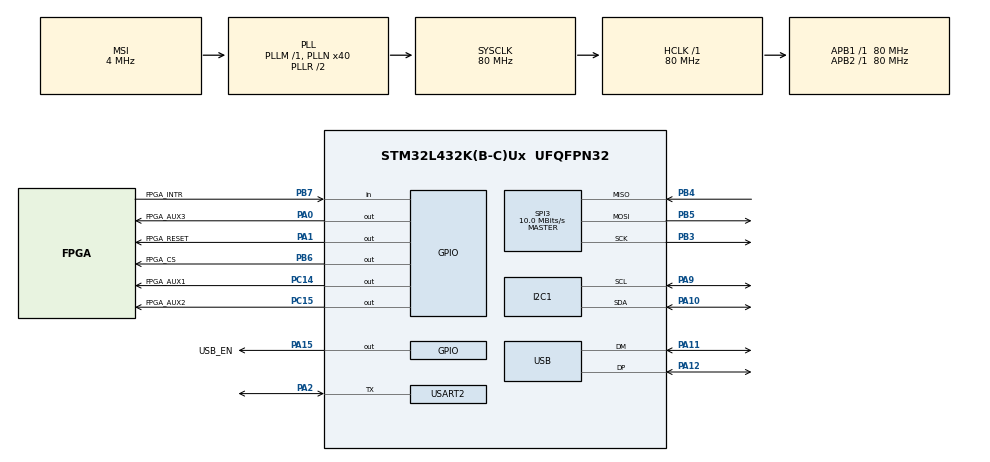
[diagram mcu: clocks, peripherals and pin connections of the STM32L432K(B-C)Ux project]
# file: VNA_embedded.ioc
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Dma.Request0=SPI3_RX
Dma.Request1=SPI3_TX
Dma.SPI3_RX.0.Direction=DMA_PERIPH_TO_MEMORY
Dma.SPI3_RX.0.Instance=DMA2_Channel1
Dma.SPI3_RX.0.MemDataAlignment=DMA_MDATAALIGN_HALFWORD
Dma.SPI3_RX.0.MemInc=DMA_MINC_ENABLE
Dma.SPI3_RX.0.Mode=DMA_NORMAL
Dma.SPI3_RX.0.PeriphDataAlignment=DMA_PDATAALIGN_HALFWORD
Dma.SPI3_RX.0.PeriphInc=DMA_PINC_DISABLE
Dma.SPI3_RX.0.Priority=DMA_PRIORITY_HIGH
Dma.SPI3_TX.1.Direction=DMA_MEMORY_TO_PERIPH
Dma.SPI3_TX.1.Instance=DMA2_Channel2
Dma.SPI3_TX.1.MemDataAlignment=DMA_MDATAALIGN_HALFWORD
Dma.SPI3_TX.1.MemInc=DMA_MINC_ENABLE
Dma.SPI3_TX.1.Mode=DMA_NORMAL
Dma.SPI3_TX.1.PeriphDataAlignment=DMA_PDATAALIGN_HALFWORD
Dma.SPI3_TX.1.PeriphInc=DMA_PINC_DISABLE
Dma.SPI3_TX.1.Priority=DMA_PRIORITY_HIGH
FREERTOS.MEMORY_ALLOCATION=1
FREERTOS.Tasks01=defaultTask,0,1024,StartDefaultTask,Default,NULL,Static,defaultTaskBuffer,defaultTaskControlBlock
Mcu.Family=STM32L4
Mcu.Name=STM32L432K(B-C)Ux
Mcu.Package=UFQFPN32
NVIC.DMA2_Channel1_IRQn=true\:5\:0\:true\:false\:true\:true\:false\:true
NVIC.DMA2_Channel2_IRQn=true\:5\:0\:true\:false\:true\:true\:false\:true
NVIC.PriorityGroup=NVIC_PRIORITYGROUP_4
NVIC.TIM1_UP_TIM16_IRQn=true\:0\:0\:false\:false\:true\:false\:false\:true
NVIC.TimeBase=TIM1_UP_TIM16_IRQn
NVIC.TimeBaseIP=TIM16
NVIC.USB_IRQn=true\:5\:0\:true\:false\:true\:true\:true\:true
PA0.GPIO_Label=FPGA_AUX3
PA0.GPIO_Speed=GPIO_SPEED_FREQ_VERY_HIGH
PA0.Signal=GPIO_Output
PA1.GPIO_Label=FPGA_RESET
PA1.GPIO_Speed=GPIO_SPEED_FREQ_VERY_HIGH
PA1.Signal=GPIO_Output
PA10.Mode=I2C
PA10.Signal=I2C1_SDA
PA11.Mode=Device
PA11.Signal=USB_DM
PA12.Mode=Device
PA12.Signal=USB_DP
PA13\ (JTMS-SWDIO).Mode=Serial_Wire
PA13\ (JTMS-SWDIO).Signal=SYS_JTMS-SWDIO
PA14\ (JTCK-SWCLK).Mode=Serial_Wire
PA14\ (JTCK-SWCLK).Signal=SYS_JTCK-SWCLK
PA15\ (JTDI).GPIO_Label=USB_EN
PA15\ (JTDI).Signal=GPIO_Output
PA2.Mode=Half_duplex(single_wire_mode)
PA2.Signal=USART2_TX
PA9.Mode=I2C
PA9.Signal=I2C1_SCL
PB3\ (JTDO-TRACESWO).Mode=Full_Duplex_Master
PB3\ (JTDO-TRACESWO).Signal=SPI3_SCK
PB4\ (NJTRST).Mode=Full_Duplex_Master
PB4\ (NJTRST).Signal=SPI3_MISO
PB5.Mode=Full_Duplex_Master
PB5.Signal=SPI3_MOSI
PB6.GPIO_Label=FPGA_CS
PB6.GPIO_Speed=GPIO_SPEED_FREQ_VERY_HIGH
PB6.Signal=GPIO_Output
PB7.GPIO_Label=FPGA_INTR
PB7.Signal=GPIO_Input
PC14-OSC32_IN\ (PC14).GPIO_Label=FPGA_AUX1
PC14-OSC32_IN\ (PC14).Signal=GPIO_Output
PC15-OSC32_OUT\ (PC15).GPIO_Label=FPGA_AUX2
PC15-OSC32_OUT\ (PC15).Signal=GPIO_Output
ProjectManager.HeapSize=0x200
ProjectManager.StackSize=0x400
ProjectManager.TargetToolchain=SW4STM32
RCC.ADCFreq_Value=48000000
RCC.AHBFreq_Value=80000000
RCC.APB1Freq_Value=80000000
RCC.APB1TimFreq_Value=80000000
RCC.APB2Freq_Value=80000000
RCC.APB2TimFreq_Value=80000000
RCC.CortexFreq_Value=80000000
RCC.HCLKFreq_Value=80000000
RCC.HSE_VALUE=8000000
RCC.HSI48_VALUE=48000000
RCC.HSI_VALUE=16000000
RCC.LSE_VALUE=32768
RCC.MSI_VALUE=4000000
RCC.PLLN=40
RCC.PLLSAI1N=24
RCC.SYSCLKFreq_VALUE=80000000
RCC.SYSCLKSource=RCC_SYSCLKSOURCE_PLLCLK
RCC.USBFreq_Value=48000000
RCC.VCOOutputFreq_Value=160000000
SPI3.BaudRatePrescaler=SPI_BAUDRATEPRESCALER_8
SPI3.CalculateBaudRate=10.0 MBits/s
SPI3.DataSize=SPI_DATASIZE_16BIT
SPI3.Direction=SPI_DIRECTION_2LINES
SPI3.Mode=SPI_MODE_MASTER
SPI3.VirtualType=VM_MASTER
TIM1.Period=65535
TIM1.Prescaler=79
USART2.VirtualMode-Half_duplex(single_wire_mode)=VM_ASYNC
VP_FREERTOS_VS_CMSIS_V1.Mode=CMSIS_V1
VP_SYS_VS_tim16.Mode=TIM16
VP_TIM1_VS_ClockSourceINT.Mode=Internal
board=custom

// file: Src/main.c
/* USER CODE BEGIN Header */
/**
  ******************************************************************************
  * @file           : main.c
  * @brief          : Main program body
  ******************************************************************************
  * @attention
  *
  * <h2><center>&copy; Copyright (c) 2020 STMicroelectronics.
  * All rights reserved.</center></h2>
  *
  * This software component is licensed by ST under Ultimate Liberty license
  * SLA0044, the "License"; You may not use this file except in compliance with
  * the License. You may obtain a copy of the License at:
  *                             www.st.com/SLA0044
  *
  ******************************************************************************
  */
/* USER CODE END Header */

#include "main.h"
#include "cmsis_os.h"

/* USER CODE BEGIN Includes */
#include "App.h"
/* USER CODE END Includes */

I2C_HandleTypeDef hi2c1;

SPI_HandleTypeDef hspi3;
DMA_HandleTypeDef hdma_spi3_rx;
DMA_HandleTypeDef hdma_spi3_tx;

TIM_HandleTypeDef htim1;

UART_HandleTypeDef huart2;

PCD_HandleTypeDef hpcd_USB_FS;

osThreadId defaultTaskHandle;
uint32_t defaultTaskBuffer[ 1024 ];
osStaticThreadDef_t defaultTaskControlBlock;

void SystemClock_Config(void);
static void MX_GPIO_Init(void);
static void MX_DMA_Init(void);
static void MX_I2C1_Init(void);
static void MX_SPI3_Init(void);
static void MX_USART2_UART_Init(void);
static void MX_TIM1_Init(void);
static void MX_USB_PCD_Init(void);
void StartDefaultTask(void const * argument);

int main(void)
{

  /* MCU Configuration--------------------------------------------------------*/

  /* Reset of all peripherals, Initializes the Flash interface and the Systick. */
  HAL_Init();

  /* Configure the system clock */
  SystemClock_Config();

  /* Initialize all configured peripherals */
  MX_GPIO_Init();
  MX_DMA_Init();
  MX_I2C1_Init();
  MX_SPI3_Init();
  MX_USART2_UART_Init();
  MX_TIM1_Init();
  MX_USB_PCD_Init();

  /* Create the thread(s) */
  /* definition and creation of defaultTask */
  osThreadStaticDef(defaultTask, StartDefaultTask, osPriorityNormal, 0, 1024, defaultTaskBuffer, &defaultTaskControlBlock);
  defaultTaskHandle = osThreadCreate(osThread(defaultTask), NULL);

  /* Start scheduler */
  osKernelStart();

  /* We should never get here as control is now taken by the scheduler */

  /* Infinite loop */
  while (1)
  {

  }
}

void SystemClock_Config(void)
{
  RCC_OscInitTypeDef RCC_OscInitStruct = {0};
  RCC_ClkInitTypeDef RCC_ClkInitStruct = {0};
  RCC_PeriphCLKInitTypeDef PeriphClkInit = {0};

  /** Initializes the CPU, AHB and APB busses clocks
  */
  RCC_OscInitStruct.OscillatorType = RCC_OSCILLATORTYPE_MSI;
  RCC_OscInitStruct.MSIState = RCC_MSI_ON;
  RCC_OscInitStruct.MSICalibrationValue = 0;
  RCC_OscInitStruct.MSIClockRange = RCC_MSIRANGE_6;
  RCC_OscInitStruct.PLL.PLLState = RCC_PLL_ON;
  RCC_OscInitStruct.PLL.PLLSource = RCC_PLLSOURCE_MSI;
  RCC_OscInitStruct.PLL.PLLM = 1;
  RCC_OscInitStruct.PLL.PLLN = 40;
  RCC_OscInitStruct.PLL.PLLP = RCC_PLLP_DIV7;
  RCC_OscInitStruct.PLL.PLLQ = RCC_PLLQ_DIV2;
  RCC_OscInitStruct.PLL.PLLR = RCC_PLLR_DIV2;
  if (HAL_RCC_OscConfig(&RCC_OscInitStruct) != HAL_OK)
  {
    Error_Handler();
  }
  /** Initializes the CPU, AHB and APB busses clocks
  */
  RCC_ClkInitStruct.ClockType = RCC_CLOCKTYPE_HCLK|RCC_CLOCKTYPE_SYSCLK
                              |RCC_CLOCKTYPE_PCLK1|RCC_CLOCKTYPE_PCLK2;
  RCC_ClkInitStruct.SYSCLKSource = RCC_SYSCLKSOURCE_PLLCLK;
  RCC_ClkInitStruct.AHBCLKDivider = RCC_SYSCLK_DIV1;
  RCC_ClkInitStruct.APB1CLKDivider = RCC_HCLK_DIV1;
  RCC_ClkInitStruct.APB2CLKDivider = RCC_HCLK_DIV1;

  if (HAL_RCC_ClockConfig(&RCC_ClkInitStruct, FLASH_LATENCY_4) != HAL_OK)
  {
    Error_Handler();
  }
  PeriphClkInit.PeriphClockSelection = RCC_PERIPHCLK_USART2|RCC_PERIPHCLK_I2C1
                              |RCC_PERIPHCLK_USB;
  PeriphClkInit.Usart2ClockSelection = RCC_USART2CLKSOURCE_PCLK1;
  PeriphClkInit.I2c1ClockSelection = RCC_I2C1CLKSOURCE_PCLK1;
  PeriphClkInit.UsbClockSelection = RCC_USBCLKSOURCE_PLLSAI1;
  PeriphClkInit.PLLSAI1.PLLSAI1Source = RCC_PLLSOURCE_MSI;
  PeriphClkInit.PLLSAI1.PLLSAI1M = 1;
  PeriphClkInit.PLLSAI1.PLLSAI1N = 24;
  PeriphClkInit.PLLSAI1.PLLSAI1P = RCC_PLLP_DIV7;
  PeriphClkInit.PLLSAI1.PLLSAI1Q = RCC_PLLQ_DIV2;
  PeriphClkInit.PLLSAI1.PLLSAI1R = RCC_PLLR_DIV2;
  PeriphClkInit.PLLSAI1.PLLSAI1ClockOut = RCC_PLLSAI1_48M2CLK;
  if (HAL_RCCEx_PeriphCLKConfig(&PeriphClkInit) != HAL_OK)
  {
    Error_Handler();
  }
  /** Configure the main internal regulator output voltage
  */
  if (HAL_PWREx_ControlVoltageScaling(PWR_REGULATOR_VOLTAGE_SCALE1) != HAL_OK)
  {
    Error_Handler();
  }
}

static void MX_I2C1_Init(void)
{

  hi2c1.Instance = I2C1;
  hi2c1.Init.Timing = 0x10909CEC;
  hi2c1.Init.OwnAddress1 = 0;
  hi2c1.Init.AddressingMode = I2C_ADDRESSINGMODE_7BIT;
  hi2c1.Init.DualAddressMode = I2C_DUALADDRESS_DISABLE;
  hi2c1.Init.OwnAddress2 = 0;
  hi2c1.Init.OwnAddress2Masks = I2C_OA2_NOMASK;
  hi2c1.Init.GeneralCallMode = I2C_GENERALCALL_DISABLE;
  hi2c1.Init.NoStretchMode = I2C_NOSTRETCH_DISABLE;
  if (HAL_I2C_Init(&hi2c1) != HAL_OK)
  {
    Error_Handler();
  }
  /** Configure Analogue filter
  */
  if (HAL_I2CEx_ConfigAnalogFilter(&hi2c1, I2C_ANALOGFILTER_ENABLE) != HAL_OK)
  {
    Error_Handler();
  }
  /** Configure Digital filter
  */
  if (HAL_I2CEx_ConfigDigitalFilter(&hi2c1, 0) != HAL_OK)
  {
    Error_Handler();
  }

}

static void MX_SPI3_Init(void)
{

  /* SPI3 parameter configuration*/
  hspi3.Instance = SPI3;
  hspi3.Init.Mode = SPI_MODE_MASTER;
  hspi3.Init.Direction = SPI_DIRECTION_2LINES;
  hspi3.Init.DataSize = SPI_DATASIZE_16BIT;
  hspi3.Init.CLKPolarity = SPI_POLARITY_LOW;
  hspi3.Init.CLKPhase = SPI_PHASE_1EDGE;
  hspi3.Init.NSS = SPI_NSS_SOFT;
  hspi3.Init.BaudRatePrescaler = SPI_BAUDRATEPRESCALER_8;
  hspi3.Init.FirstBit = SPI_FIRSTBIT_MSB;
  hspi3.Init.TIMode = SPI_TIMODE_DISABLE;
  hspi3.Init.CRCCalculation = SPI_CRCCALCULATION_DISABLE;
  hspi3.Init.CRCPolynomial = 7;
  hspi3.Init.CRCLength = SPI_CRC_LENGTH_DATASIZE;
  hspi3.Init.NSSPMode = SPI_NSS_PULSE_ENABLE;
  if (HAL_SPI_Init(&hspi3) != HAL_OK)
  {
    Error_Handler();
  }

}

static void MX_TIM1_Init(void)
{

  TIM_ClockConfigTypeDef sClockSourceConfig = {0};
  TIM_MasterConfigTypeDef sMasterConfig = {0};

  htim1.Instance = TIM1;
  htim1.Init.Prescaler = 79;
  htim1.Init.CounterMode = TIM_COUNTERMODE_UP;
  htim1.Init.Period = 65535;
  htim1.Init.ClockDivision = TIM_CLOCKDIVISION_DIV1;
  htim1.Init.RepetitionCounter = 0;
  htim1.Init.AutoReloadPreload = TIM_AUTORELOAD_PRELOAD_DISABLE;
  if (HAL_TIM_Base_Init(&htim1) != HAL_OK)
  {
    Error_Handler();
  }
  sClockSourceConfig.ClockSource = TIM_CLOCKSOURCE_INTERNAL;
  if (HAL_TIM_ConfigClockSource(&htim1, &sClockSourceConfig) != HAL_OK)
  {
    Error_Handler();
  }
  sMasterConfig.MasterOutputTrigger = TIM_TRGO_RESET;
  sMasterConfig.MasterOutputTrigger2 = TIM_TRGO2_RESET;
  sMasterConfig.MasterSlaveMode = TIM_MASTERSLAVEMODE_DISABLE;
  if (HAL_TIMEx_MasterConfigSynchronization(&htim1, &sMasterConfig) != HAL_OK)
  {
    Error_Handler();
  }

}

static void MX_USART2_UART_Init(void)
{

  huart2.Instance = USART2;
  huart2.Init.BaudRate = 115200;
  huart2.Init.WordLength = UART_WORDLENGTH_8B;
  huart2.Init.StopBits = UART_STOPBITS_1;
  huart2.Init.Parity = UART_PARITY_NONE;
  huart2.Init.Mode = UART_MODE_TX_RX;
  huart2.Init.HwFlowCtl = UART_HWCONTROL_NONE;
  huart2.Init.OverSampling = UART_OVERSAMPLING_16;
  huart2.Init.OneBitSampling = UART_ONE_BIT_SAMPLE_DISABLE;
  huart2.AdvancedInit.AdvFeatureInit = UART_ADVFEATURE_NO_INIT;
  if (HAL_HalfDuplex_Init(&huart2) != HAL_OK)
  {
    Error_Handler();
  }

}

static void MX_USB_PCD_Init(void)
{

  hpcd_USB_FS.Instance = USB;
  hpcd_USB_FS.Init.dev_endpoints = 8;
  hpcd_USB_FS.Init.speed = PCD_SPEED_FULL;
  hpcd_USB_FS.Init.phy_itface = PCD_PHY_EMBEDDED;
  hpcd_USB_FS.Init.Sof_enable = DISABLE;
  hpcd_USB_FS.Init.low_power_enable = DISABLE;
  hpcd_USB_FS.Init.lpm_enable = DISABLE;
  hpcd_USB_FS.Init.battery_charging_enable = DISABLE;
  if (HAL_PCD_Init(&hpcd_USB_FS) != HAL_OK)
  {
    Error_Handler();
  }

}

static void MX_DMA_Init(void)
{
  /* DMA controller clock enable */
  __HAL_RCC_DMA2_CLK_ENABLE();

  /* DMA interrupt init */
  /* DMA2_Channel1_IRQn interrupt configuration */
  HAL_NVIC_SetPriority(DMA2_Channel1_IRQn, 5, 0);
  HAL_NVIC_EnableIRQ(DMA2_Channel1_IRQn);
  /* DMA2_Channel2_IRQn interrupt configuration */
  HAL_NVIC_SetPriority(DMA2_Channel2_IRQn, 5, 0);
  HAL_NVIC_EnableIRQ(DMA2_Channel2_IRQn);

}

static void MX_GPIO_Init(void)
{
  GPIO_InitTypeDef GPIO_InitStruct = {0};

  /* GPIO Ports Clock Enable */
  __HAL_RCC_GPIOC_CLK_ENABLE();
  __HAL_RCC_GPIOA_CLK_ENABLE();
  __HAL_RCC_GPIOB_CLK_ENABLE();

  /*Configure GPIO pin Output Level */
  HAL_GPIO_WritePin(GPIOC, FPGA_AUX1_Pin|FPGA_AUX2_Pin, GPIO_PIN_RESET);

  /*Configure GPIO pin Output Level */
  HAL_GPIO_WritePin(GPIOA, FPGA_AUX3_Pin|FPGA_RESET_Pin|USB_EN_Pin, GPIO_PIN_RESET);

  /*Configure GPIO pin Output Level */
  HAL_GPIO_WritePin(FPGA_CS_GPIO_Port, FPGA_CS_Pin, GPIO_PIN_RESET);

  /*Configure GPIO pins : FPGA_AUX1_Pin FPGA_AUX2_Pin */
  GPIO_InitStruct.Pin = FPGA_AUX1_Pin|FPGA_AUX2_Pin;
  GPIO_InitStruct.Mode = GPIO_MODE_OUTPUT_PP;
  GPIO_InitStruct.Pull = GPIO_NOPULL;
  GPIO_InitStruct.Speed = GPIO_SPEED_FREQ_LOW;
  HAL_GPIO_Init(GPIOC, &GPIO_InitStruct);

  /*Configure GPIO pins : FPGA_AUX3_Pin FPGA_RESET_Pin */
  GPIO_InitStruct.Pin = FPGA_AUX3_Pin|FPGA_RESET_Pin;
  GPIO_InitStruct.Mode = GPIO_MODE_OUTPUT_PP;
  GPIO_InitStruct.Pull = GPIO_NOPULL;
  GPIO_InitStruct.Speed = GPIO_SPEED_FREQ_VERY_HIGH;
  HAL_GPIO_Init(GPIOA, &GPIO_InitStruct);

  /*Configure GPIO pin : USB_EN_Pin */
  GPIO_InitStruct.Pin = USB_EN_Pin;
  GPIO_InitStruct.Mode = GPIO_MODE_OUTPUT_PP;
  GPIO_InitStruct.Pull = GPIO_NOPULL;
  GPIO_InitStruct.Speed = GPIO_SPEED_FREQ_LOW;
  HAL_GPIO_Init(USB_EN_GPIO_Port, &GPIO_InitStruct);

  /*Configure GPIO pin : FPGA_CS_Pin */
  GPIO_InitStruct.Pin = FPGA_CS_Pin;
  GPIO_InitStruct.Mode = GPIO_MODE_OUTPUT_PP;
  GPIO_InitStruct.Pull = GPIO_NOPULL;
  GPIO_InitStruct.Speed = GPIO_SPEED_FREQ_VERY_HIGH;
  HAL_GPIO_Init(FPGA_CS_GPIO_Port, &GPIO_InitStruct);

  /*Configure GPIO pin : FPGA_INTR_Pin */
  GPIO_InitStruct.Pin = FPGA_INTR_Pin;
  GPIO_InitStruct.Mode = GPIO_MODE_INPUT;
  GPIO_InitStruct.Pull = GPIO_NOPULL;
  HAL_GPIO_Init(FPGA_INTR_GPIO_Port, &GPIO_InitStruct);

}

void StartDefaultTask(void const * argument)
{

  /* USER CODE BEGIN 5 */
  App_Start();
  /* Infinite loop */
  for(;;)
  {
    osDelay(1);
  }
  /* USER CODE END 5 */
}

void HAL_TIM_PeriodElapsedCallback(TIM_HandleTypeDef *htim)
{
  if (htim->Instance == TIM16) {
    HAL_IncTick();
  }
}

void Error_Handler(void)
{
}

/************************ (C) COPYRIGHT STMicroelectronics *****END OF FILE****/
